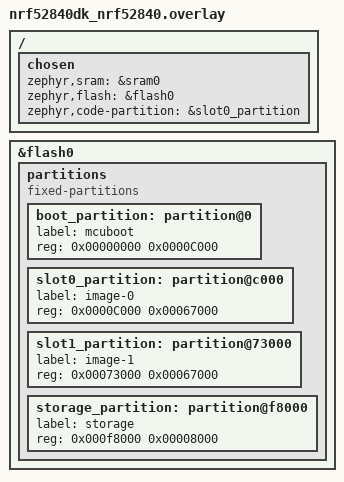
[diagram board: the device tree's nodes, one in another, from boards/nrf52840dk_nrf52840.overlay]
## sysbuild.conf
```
# Sysbuild configuration file.

# Enable MCUboot per default for this sample.
SB_CONFIG_BOOTLOADER_MCUBOOT=y
SB_CONFIG_BOOT_SIGNATURE_TYPE_RSA=y
SB_CONFIG_BOOT_SIGNATURE_KEY_FILE="\${APPLICATION_CONFIG_DIR}/sysbuild/nofence_rsa_private.pem"

SB_CONFIG_MCUBOOT_MODE_SWAP_USING_MOVE=y
# SB_CONFIG_MCUBOOT_MODE_SWAP_USING_OFFSET=y
# SB_CONFIG_MCUBOOT_MODE_OVERWRITE_ONLY=y
SB_CONFIG_PARTITION_MANAGER=y
```

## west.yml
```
manifest:
  self:
    path: app

  defaults:
    remote: nrfconnect

  remotes:
    - name: nrfconnect
      url-base: https://github.com/nrfconnect

  projects:
    - name: nrf
      remote: nrfconnect
      repo-path: sdk-nrf
      revision: main
      import: true
```

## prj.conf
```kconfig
# Print a banner on the UART on startup.
# CONFIG_BOOT_BANNER=y
CONFIG_NCS_BOOT_BANNER=y

CONFIG_REBOOT=y

# Enable console and printk()
CONFIG_PRINTK=y
CONFIG_STDOUT_CONSOLE=y

CONFIG_GPIO=y

CONFIG_BOOTLOADER_MCUBOOT=y
CONFIG_IMG_MANAGER=y
CONFIG_MCUBOOT_IMG_MANAGER=y

# Logging
# CONFIG_LOG=y
# CONFIG_USE_SEGGER_RTT=y
# CONFIG_RTT_CONSOLE=y
# CONFIG_CONSOLE=y
# CONFIG_LOG_MODE_MINIMAL=n
# CONFIG_LOG_MODE_IMMEDIATE=y
# CONFIG_SEGGER_RTT_BUFFER_SIZE_UP=8192

# Flash
CONFIG_FLASH=y
CONFIG_FLASH_PAGE_LAYOUT=y
CONFIG_MPU_ALLOW_FLASH_WRITE=y
CONFIG_FLASH_MAP=y
CONFIG_MCUBOOT_TRAILER_SWAP_TYPE=y
CONFIG_STREAM_FLASH=y
CONFIG_HEAP_MEM_POOL_SIZE=8192
CONFIG_MAIN_STACK_SIZE=8192

CONFIG_DEBUG=y
CONFIG_DEBUG_OPTIMIZATIONS=y



#SETTINGS
CONFIG_NVS=y
CONFIG_SETTINGS=y
CONFIG_SETTINGS_NVS=y
CONFIG_SETTINGS_RUNTIME=n
```

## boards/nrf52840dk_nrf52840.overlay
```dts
/ {
	chosen {
		zephyr,sram = &sram0;
		zephyr,flash = &flash0;
		zephyr,code-partition = &slot0_partition;
	};
};

&flash0 {
	/delete-node/ partitions;

	partitions {

		compatible = "fixed-partitions";
		#address-cells = <1>;
		#size-cells = <1>;

		boot_partition: partition@0 {
			label = "mcuboot";
			reg = <0x00000000 0x0000C000>;
		};

		slot0_partition: partition@c000 {
			label = "image-0";
			reg = <0x0000C000 0x00067000>;
		};

		slot1_partition: partition@73000 {
			label = "image-1";
			reg = <0x00073000 0x00067000>;
		};
		
		
		storage_partition: partition@f8000 {
			label = "storage";
			reg = <0x000f8000 0x00008000>;
		};
	};
};
```

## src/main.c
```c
/*
 * Copyright (c) 2016 Intel Corporation
 *
 * SPDX-License-Identifier: Apache-2.0
 */

#include "delta/delta.h"
#include <zephyr/drivers/gpio.h>
#include <zephyr/kernel.h>
#include <zephyr/sys/printk.h>
#include <zephyr/sys/util.h>

/* BUTTON */
#define SW0_NODE DT_ALIAS(sw0)
#if !DT_NODE_HAS_STATUS(SW0_NODE, okay)
#error "Unsupported board: sw0 devicetree alias is not defined"
#endif
static const struct gpio_dt_spec button =
    GPIO_DT_SPEC_GET_OR(SW0_NODE, gpios, {0});

static struct gpio_callback button_cb_data;
static bool btn_flag;

/* LED */
#define SLEEP_TIME_MS 250 /*BLINKING SPEED*/

#define LED0_NODE DT_ALIAS(led2)

/*
 * A build error on this line means your board is unsupported.
 * See the sample documentation for information on how to fix this.
 */
static const struct gpio_dt_spec led = GPIO_DT_SPEC_GET(LED0_NODE, gpios);

static const struct device *flash_device =
    DEVICE_DT_GET_OR_NULL(DT_CHOSEN(zephyr_flash_controller));

/* Debug printouts (adds about 800 B to img)
 * Define to 0 to disable
 */
#ifndef PRINT_ERRORS
#define PRINT_ERRORS 1
#endif

/*Initiating button and led*/
static int config_devices(void);

/*Responds to button 1 being pressed*/
void button_pressed(const struct device *dev, struct gpio_callback *cb,
                    uint32_t pins);

/* MAIN FUNCTION */
int main(void) {
  struct flash_mem *flash_pt;
  int ret;

  flash_pt = k_malloc(sizeof(struct flash_mem));
  flash_pt->device = flash_device;

  if (!flash_pt->device) {
    return -1;
  }
  if (config_devices()) {
    return -1;
  }

  /*Main loop*/
  while (1) {
    /* turn light on/off */
    ret = gpio_pin_toggle_dt(&led);
    if (ret < 0) {
      return -1;
    }
    k_msleep(SLEEP_TIME_MS);

    if (btn_flag) {
      ret = delta_check_and_apply(flash_pt);
      if (ret) {
#if PRINT_ERRORS == 1
        printk("%s", delta_error_as_string(ret));
#endif
        return -1;
      }
      btn_flag = false;
    }
  }
  return 0;
}

static int config_devices(void) {
  int ret;

  /* setup led */
  if (!gpio_is_ready_dt(&led)) {
    return -1;
  }

  ret = gpio_pin_configure_dt(&led, GPIO_OUTPUT_ACTIVE);
  if (ret < 0) {
    return -1;
  }

  /*setup button*/
  if (!gpio_is_ready_dt(&button)) {
    return -1;
  }

  ret = gpio_pin_configure_dt(&button, GPIO_INPUT);
  if (ret) {
    return -1;
  }

  ret = gpio_pin_interrupt_configure_dt(&button, GPIO_INT_EDGE_TO_ACTIVE);
  if (ret) {
    return -1;
  }

  gpio_init_callback(&button_cb_data, button_pressed, BIT(button.pin));
  gpio_add_callback(button.port, &button_cb_data);

  btn_flag = false;

  return 0;
}

void button_pressed(const struct device *dev, struct gpio_callback *cb,
                    uint32_t pins) {
  printk("Button pressed at %" PRIu32 "\n", k_cycle_get_32());
  btn_flag = true;
}
```
